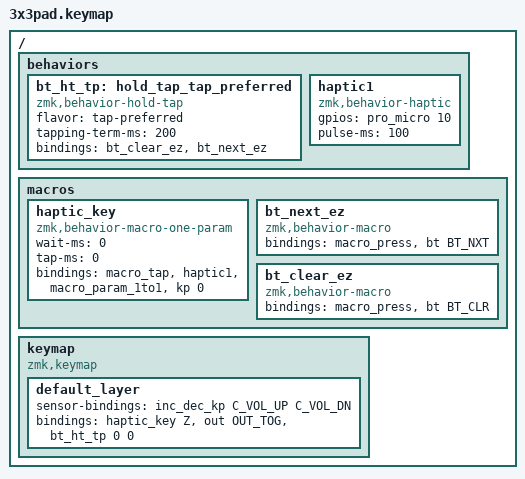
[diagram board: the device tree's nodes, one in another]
#include <behaviors.dtsi>
#include <dt-bindings/zmk/keys.h>
#include <dt-bindings/zmk/bt.h>
#include <dt-bindings/zmk/outputs.h>

/ {
    behaviors {
        bt_ht_tp: hold_tap_tap_preferred {
            compatible = "zmk,behavior-hold-tap";
            #binding-cells = <2>;
            flavor = "tap-preferred";
            tapping-term-ms = <200>;
            bindings = <&bt_clear_ez>, <&bt_next_ez>;
        };

        haptic1: haptic1 {
            compatible = "zmk,behavior-haptic";
            #binding-cells = <0>;

            gpios = <&pro_micro 10 GPIO_ACTIVE_HIGH>;
            pulse-ms = <100>;
        };
    };

     macros {
        haptic_key: haptic_key {
            compatible = "zmk,behavior-macro-one-param";
            #binding-cells = <1>;
            wait-ms = <0>;
            tap-ms = <0>;
            bindings
                = <&macro_tap &haptic1>
                , <&macro_param_1to1>
                , <&kp 0>
                ;
        };

        bt_next_ez: bt_next_ez {
            compatible = "zmk,behavior-macro";
            #binding-cells = <0>;
            bindings = <&macro_press &bt BT_NXT>;
        };

        bt_clear_ez: bt_clear_ez {
            compatible = "zmk,behavior-macro";
            #binding-cells = <0>;
            bindings = <&macro_press &bt BT_CLR>;
        };
    };

    keymap {
        compatible = "zmk,keymap";

        default_layer { // Layer 0
            sensor-bindings = <&inc_dec_kp C_VOL_UP C_VOL_DN>;

            // -------------------------------------
            // |     Z     |     M     |     K     |
            // |     A     |     B     |     C     |
            // |     D     |     E     |     F     |
            bindings = <
                &haptic_key Z    &out OUT_TOG
                &bt_ht_tp 0 0
            >;
        };
    };
 };
